# R7FA6T2BD register map
Vendor: Renesas Electronics Corporation; Series: RA6; File version: 1.40.00
CPU: CM33 r0p4, little endian, MPU, FPU, VTOR, 4 interrupt priority bits, 96 interrupts
Registers are 32-bit, read-write, reset 0x0 unless marked. A register's access mark holds for its fields unless they carry their own. Offsets are from the block's base; [hi:lo] are bit positions; lines under a group give offsets from that group; {n}, {i} and the like mark numbered series; 'fields as' and 'values as' point back to an identical list.

## ADC_B — 12-bit A/D Converter
Base 0x40170000
0x00 ADCLKENR — A/D Conversion Clock Enable Register
  [0] CLKEN — ADCLK Operating Enable
    0=Stop ADCLK; 1=Supply ADCLK
0x04 ADCLKSR ro — A/D Conversion Clock Status Register
  [0] CLKSR — ADCLK status
    0=ADCLK is stopped; 1=ADCLK is in supply
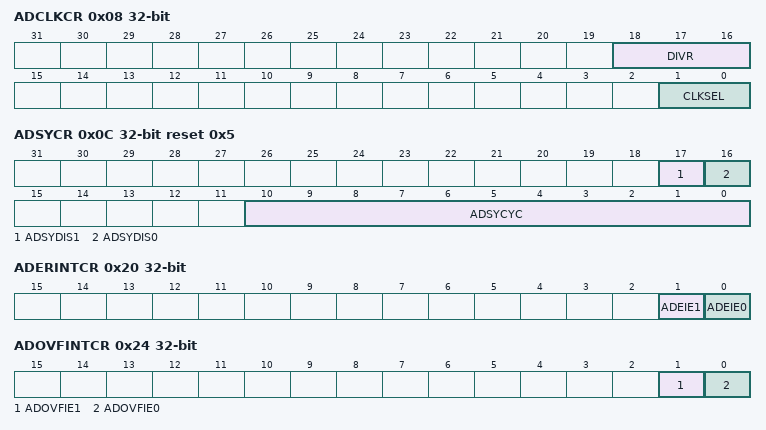
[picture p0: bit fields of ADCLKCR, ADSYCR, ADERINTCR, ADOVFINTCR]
0x08 ADCLKCR — A/D Conversion Clock Control Register
  [18:16] DIVR — Clock Division Ratio Select
    {v}=1/{v+1} (v=0..7)
  [1:0] CLKSEL — ADCLK Clock Source Select
    0=Peripheral Module Clock C (PCLKC); 1=GPT clock (GPTCLK); 2=Peripheral Module Clock A (PCLKA); 3=Setting prohibited
0x0C ADSYCR reset 0x5 — A/D Converter Synchronous Operation Control Register
  [17] ADSYDIS1 — ADC1 Synchronous Operation Select
    0=Enable ADC1 synchronous operation; 1=Disable ADC1 synchronous operation
  [16] ADSYDIS0 — ADC0 Synchronous Operation Select
    0=Enable ADC0 synchronous operation; 1=Disable ADC0 synchronous operation
  [10:0] ADSYCYC — Synchronous Operation Period Cycle
0x20 ADERINTCR — A/D Conversion Error Interrupt Enable Register
  [1] ADEIE1 — ADC1 A/D Conversion Error Interrupt Enable
    0=Disable A/D conversion error interrupt for ADC1; 1=Enable A/D conversion error interrupt for ADC1
  [0] ADEIE0 — ADC0 A/D Conversion Error Interrupt Enable
    0=Disable A/D conversion error interrupt for ADC0; 1=Enable A/D conversion error interrupt for ADC0
0x24 ADOVFINTCR — A/D Conversion Overflow Interrupt Enable Register
  [1] ADOVFIE1 — ADC1 A/D Conversion Overflow Interrupt Enable
    0=Disable A/D conversion overflow interrupt for ADC1; 1=Enable A/D conversion overflow interrupt for ADC1
  [0] ADOVFIE0 — ADC0 A/D Conversion Overflow Interrupt Enable
    0=Disable A/D conversion overflow interrupt for ADC0; 1=Enable A/D conversion overflow interrupt for ADC0
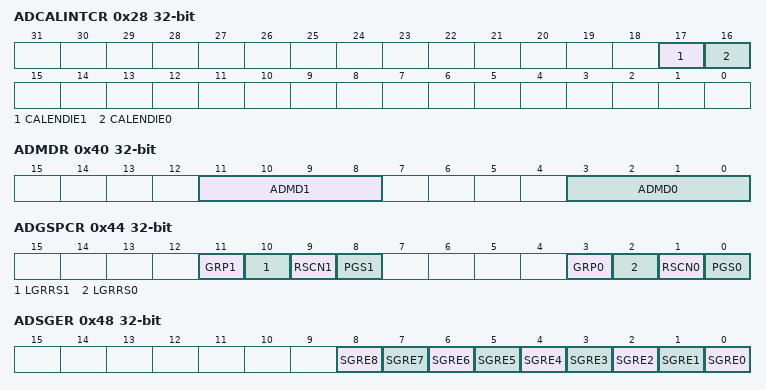
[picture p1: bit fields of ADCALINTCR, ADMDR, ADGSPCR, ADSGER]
0x28 ADCALINTCR — Calibration interrupt Enable Register
  [17] CALENDIE1 — ADC1 Calibration End Interrupt Enable
    0=Disable Calibration End Interrupt for ADC1; 1=Enable Calibration End Interrupt for ADC1
  [16] CALENDIE0 — ADC0 Calibration End Interrupt Enable
    0=Disable Calibration End Interrupt for ADC0; 1=Enable Calibration End Interrupt for ADC0
0x40 ADMDR — A/D Converter Mode Selection Register
  [11:8] ADMD1 — ADC1 Mode Selection
    0=SAR mode – Single scan mode; 1=SAR mode – Continuous scan mode; 4=Oversampling mode – Single scan mode; 5=Oversampling mode – Continuous scan mode; 8=Hybrid mode – Single scan mode; 9=Hybrid mode – Continuous scan mode; 10=Hybrid mode – Background continuous scan mode; other=Others (Setting prohibited)
  [3:0] ADMD0 — ADC0 Mode Selection
    values as ADMD1
0x44 ADGSPCR — A/D Group scan Priority Control Register
  [11] GRP1 — ADC1 Group Priority Control Setting 4
    0=Set the following case: When PGS1 is set to 0When PGS1 is set to 1 and ADC1 is SAR mode – Single scan mode; 1=Set when PGS1 is set to 1 and ADC1 is SAR mode – Continuous scan mode
  [10] LGRRS1 — ADC1 Group Priority Control Setting 3
    0=Set when PGS1 is set to 0; 1=Set when PGS1 is set to 1
  [9] RSCN1 — ADC1 Group Priority Control Setting 2
    0=Set when PGS1 is set to 0; 1=Set when PGS1 is set to 1
  [8] PGS1 — ADC1 Group Priority Control Setting
    0=ADC1 operation is without group priority control; 1=ADC1 operation is with group priority control in SAR mode. Setting prohibited when other than SAR mode.
  [3] GRP0 — ADC0 Group Priority Control Setting 4
    0=Set the following case: When PGS0 is set to 0When PGS0 is set to 1 and ADC0 is SAR mode – Single scan mode; 1=Set when PGS0 is set to 1 and ADC0 is SAR mode – Continuous scan mode
  [2] LGRRS0 — ADC0 Group Priority Control Setting 3
    0=Set when PGS0 is set to 0; 1=Set when PGS0 is set to 1
  [1] RSCN0 — ADC0 Group Priority Control Setting 2
    0=Set when PGS0 is set to 0; 1=Set when PGS0 is set to 1
  [0] PGS0 — ADC0 Group Priority Control Setting
    0=ADC0 operation is without group priority control; 1=ADC0 operation is with group priority control in SAR mode. Setting prohibited when other than SAR mode.
0x48 ADSGER — Scan Group Enable Register
  [all] fields
    0=Disable the scan group n; 1=Enable the scan group n
  [n] SGRE{n} (n=0..8) — Scan Group n Enable
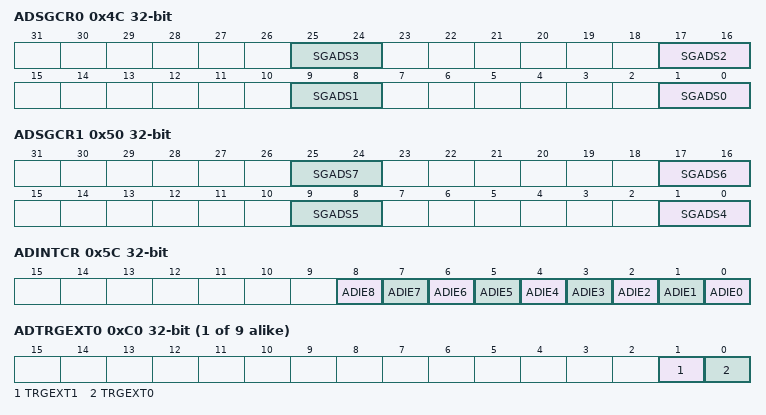
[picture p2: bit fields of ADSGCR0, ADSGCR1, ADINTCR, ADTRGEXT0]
0x4C ADSGCR0 — Scan Group Control Register 0
  [all] fields
    0=Select ADC0; 1=Select ADC1; other=Others (Setting prohibited)
  [8n+1:8n] SGADS{n} (n=0..3) — Scan Group {n} A/D Converter Selection
0x50 ADSGCR1 — Scan Group Control Register 1
  [all] fields
    values as the fields of ADSGCR0
  [8n-31:8n-32] SGADS{n} (n=4..7) — Scan Group {n} A/D Converter Selection
0x54 ADSGCR2 — Scan Group Control Register 2
  [1:0] SGADS8 — Scan Group 8 A/D Converter Selection
    values as the fields of ADSGCR0
0x5C ADINTCR — Scan End Interrupt Enable Register
  [all] fields
    0=Disable scan end interrupt; 1=Enable scan end interrupt
  [n] ADIE{n} (n=0..8) — Scan Group n Scan End Interrupt Enable
{0xC0+0x10*i} ADTRGEXT{i} (i=0..8) — External Trigger Enable Register {i}
  [1] TRGEXT1 — External Trigger Input 1 (ADTRG1) Enable
    0=Disable ADTRG1; 1=Enable ADTRG1
  [0] TRGEXT0 — External Trigger Input 0 (ADTRG0) Enable
    0=Disable ADTRG0; 1=Enable ADTRG0
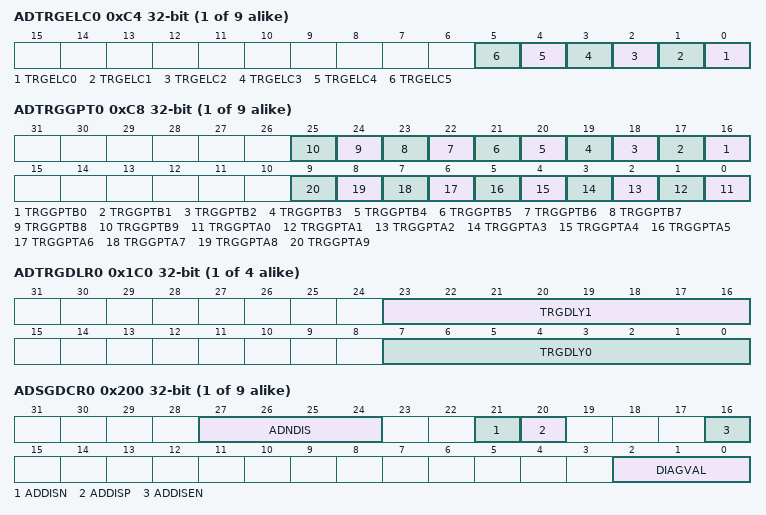
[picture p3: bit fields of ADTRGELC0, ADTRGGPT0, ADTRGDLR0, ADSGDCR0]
{0xC4+0x10*i} ADTRGELC{i} (i=0..8) — ELC Trigger Enable Register {i}
  [all] fields
    0=Disable ELC Trigger m; 1=Enable ELC Trigger m
  [n] TRGELC{n} (n=0..5) — ELC Trigger m Enable
{0xC8+0x10*i} ADTRGGPT{i} (i=0..8) — GPT Trigger Enable Register {i}
  [n+16] TRGGPTB{n} (n=0..9) — GPT channel m A/D Conversion Starting Request B Enable
    0=Disable the A/D conversion stating request B from GPT channel m; 1=Enable the A/D conversion stating request B from GPT channel m
  [n] TRGGPTA{n} (n=0..9) — GPT channel m A/D Conversion Starting Request A Enable
    0=Disable the A/D conversion stating request A from GPT channel m; 1=Enable the A/D conversion stating request A from GPT channel m
{0x1C0+4i} ADTRGDLR{i} (i=0..3) — A/D Conversion Start Trigger Delay Register {i}
  [23:16] TRGDLY{2i+1} — Scan Group {2i+1} Trigger Input Delay Configuration
  [7:0] TRGDLY{2i} — Scan Group {2i} Trigger Input Delay Configuration
0x1D0 ADTRGDLR4 — A/D Conversion Start Trigger Delay Register 4
  [7:0] TRGDLY8 — Scan Group 8 Trigger Input Delay Configuration
{0x200+4i} ADSGDCR{i} (i=0..8) — Scan Group Diagnosis Function Control Register {i}
  [27:24] ADNDIS — Disconnection Detection Assist Period
    0=Setting prohibited when the disconnection detection assist function is enabled; 1=Setting prohibited; 2=Setting prohibited; other=Others (The number of states for the discharge or precharge period)
  [21] ADDISN — Disconnection Detection Assist Mode Selection
    0=Discharge; 1=Precharge
  [20] ADDISP — Disconnection Detection Assist Mode Selection
    0=Discharge; 1=Precharge
  [16] ADDISEN — Disconnection Detection Assist Enable
    0=Disable the disconnection detection assist function; 1=Enable the disconnection detection assist function
  [2:0] DIAGVAL — Self-diagnosis Mode Selection
    0=Set when any self-diagnosis channel are not included. Setting prohibited when any self-diagnosis channels are included.; 4=Self-diagnosis mode 1; 5=Self-diagnosis mode 2; 6=Self-diagnosis mode 3; other=Others (Setting prohibited)
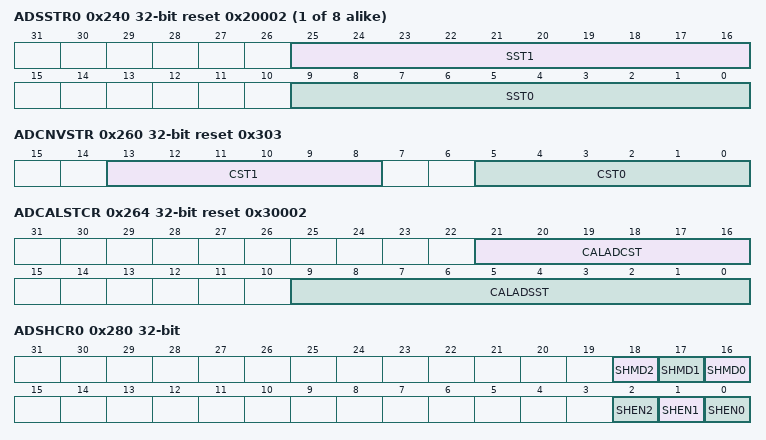
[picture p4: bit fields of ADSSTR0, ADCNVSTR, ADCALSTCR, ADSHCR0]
{0x240+4i} ADSSTR{i} reset 0x20002 (i=0..7) — Sampling State Table Register {i}
  [25:16] SST{2i+1} — Sampling State Table {2i+1}
  [9:0] SST{2i} — Sampling State Table {2i}
0x260 ADCNVSTR reset 0x303 — A/D Conversion State Register
  [13:8] CST1 — A/D Converter Unit 1 (ADC1)
  [5:0] CST0 — A/D Converter Unit 0 (ADC0)
0x264 ADCALSTCR reset 0x30002 — A/D Converter Self-calibration State Register
  [21:16] CALADCST — A/D Converter Self-calibration Successive Approximation Time Configuration.
  [9:0] CALADSST — A/D Converter Self-calibration Sampling Time Configuration
0x280 ADSHCR0 — Channel-dedicated Sample-and-hold Circuit Control Register 0
  [18] SHMD2 — Channel-dedicated Sample-and-hold Circuit Unit 2 Input Mode Select
    0=Single-ended Input mode; 1=Differential Input mode
  [17] SHMD1 — Channel-dedicated Sample-and-hold Circuit Unit 1 Input Mode Select
    0=Single-ended Input mode; 1=Differential Input mode
  [16] SHMD0 — Channel-dedicated Sample-and-hold Circuit Unit 0 Input Mode Select
    0=Single-ended Input mode; 1=Differential Input mode
  [2] SHEN2 — Channel-dedicated Sample-and-hold Circuit Unit 2 Select
    0=Bypass the circuit unit 2; 1=Use the circuit unit 2
  [1] SHEN1 — Channel-dedicated Sample-and-hold Circuit Unit 1 Select
    0=Bypass the circuit unit 1; 1=Use the circuit unit 1
  [0] SHEN0 — Channel-dedicated Sample-and-hold Circuit Unit 0 Select
    0=Bypass the circuit unit 0; 1=Use the circuit unit 0
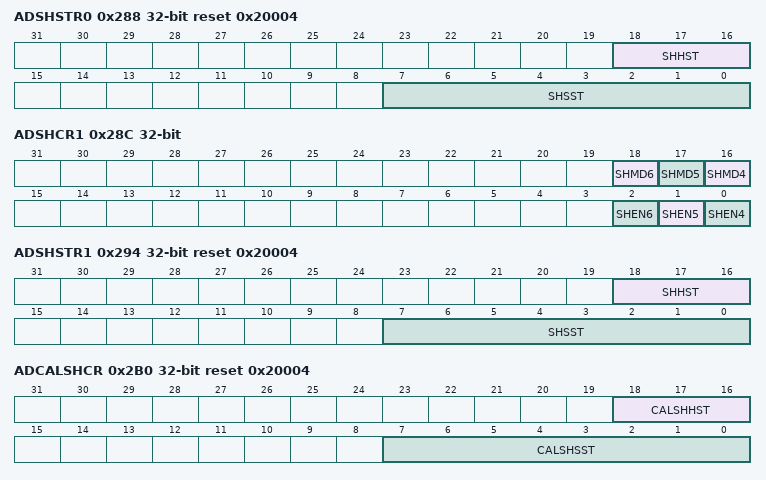
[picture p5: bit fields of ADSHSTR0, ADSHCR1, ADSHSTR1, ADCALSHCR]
0x288 ADSHSTR0 reset 0x20004 — Channel-dedicated Sample-and-hold Circuit State Register 0
  [18:16] SHHST — Channel-dedicated Sample-and-hold Circuit Unit 0 to 2
  [7:0] SHSST — Channel-dedicated Sample-and-hold Circuit Unit 0 to 2
0x28C ADSHCR1 — Channel-dedicated Sample-and-hold Circuit Control Register 1
  [18] SHMD6 — Channel-dedicated Sample-and-hold Circuit Unit 6 Input Mode Select
    0=Single-ended Input mode; 1=Differential Input mode
  [17] SHMD5 — Channel-dedicated Sample-and-hold Circuit Unit 5 Input Mode Select
    0=Single-ended Input mode; 1=Differential Input mode
  [16] SHMD4 — Channel-dedicated Sample-and-hold Circuit Unit 4 Input Mode Select
    0=Single-ended Input mode; 1=Differential Input mode
  [2] SHEN6 — Channel-dedicated Sample-and-hold Circuit Unit 6 Select
    0=Bypass the circuit unit 6; 1=Use the circuit unit 6
  [1] SHEN5 — Channel-dedicated Sample-and-hold Circuit Unit 5 Select
    0=Bypass the circuit unit 5; 1=Use the circuit unit 5
  [0] SHEN4 — Channel-dedicated Sample-and-hold Circuit Unit 4 Select
    0=Bypass the circuit unit 4; 1=Use the circuit unit 4
0x294 ADSHSTR1 reset 0x20004 — Channel-dedicated Sample-and-hold Circuit State Register 1
  [18:16] SHHST — Channel-dedicated Sample-and-hold Circuit Unit 4 to 6
  [7:0] SHSST — Channel-dedicated Sample-and-hold Circuit Unit 4 to 6
0x2B0 ADCALSHCR reset 0x20004 — Channel-dedicated Sample-and-hold Circuit Self-calibration State Register
  [18:16] CALSHHST — Channel-dedicated Sample-and-hold Circuit Self-calibration Hold Mode Switching Time Configuration
  [7:0] CALSHSST — Channel-dedicated Sample-and-hold Circuit Self-calibration Sampling Time Configuration
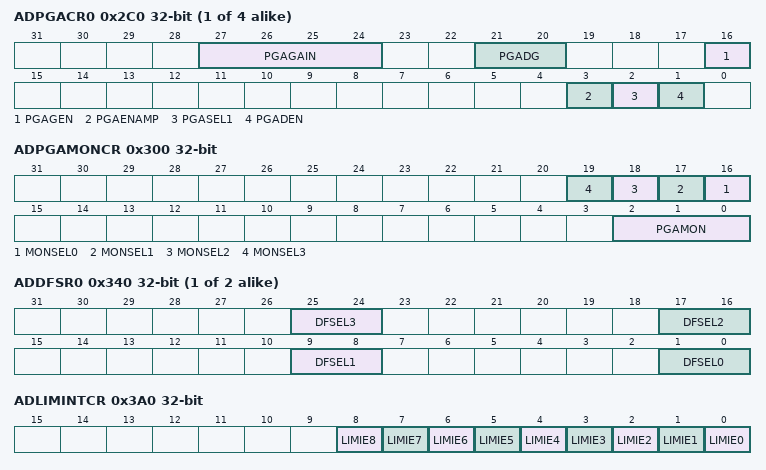
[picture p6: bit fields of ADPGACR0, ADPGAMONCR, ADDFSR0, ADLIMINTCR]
{0x2C0+4i} ADPGACR{i} (i=0..3) (reset mask 0xFFFFFFFD) — Programmable Gain Amplifier Control Register {i}
  [27:24] PGAGAIN — PGA Unit n Gain Setting
    0=× 2.000 (PGA is Single-ended Input mode) Setting prohibited (PGA is Pseudo-differential Input mode); 1=× 2.500 (PGA is Single-ended Input mode) × 1.500 (PGA is Pseudo-differential Input mode); 2=× 2.667 (PGA is Single-ended Input mode) Setting prohibited (PGA is Pseudo-differential Input mode); 3=× 2.857 (PGA is Single-ended Input mode) Setting prohibited (PGA is Pseudo-differential Input mode); 4=× 3.077 (PGA is Single-ended Input mode) Setting prohibited (PGA is Pseudo-differential Input mode); 5=× 3.333 (PGA is Single-ended Input mode) × 2.333 (PGA is Pseudo-differential Input mode); 6=× 3.636 (PGA is Single-ended Input mode) Setting prohibited (PGA is Pseudo-differential Input mode); 7=× 4.000 (PGA is Single-ended Input mode) Setting prohibited (PGA is Pseudo-differential Input mode); 8=× 4.444 (PGA is Single-ended Input mode) Setting prohibited (PGA is Pseudo-differential Input mode); 9=× 5.000 (PGA is Single-ended Input mode) × 4.000 (PGA is Pseudo-differential Input mode); 10=× 5.714 (PGA is Single-ended Input mode) Setting prohibited (PGA is Pseudo-differential Input mode); 11=× 6.667 (PGA is Single-ended Input mode) × 5.667 (PGA is Pseudo-differential Input mode); 12=× 8.000 (PGA is Single-ended Input mode) Setting prohibited (PGA is Pseudo-differential Input mode); 13=× 10.000 (PGA is Single-ended Input mode) Setting prohibited (PGA is Pseudo-differential Input mode); 14=× 13.333 (PGA is Single-ended Input mode) Setting prohibited (PGA is Pseudo-differential Input mode); 15=Setting prohibited
  [21:20] PGADG — PGA Unit n Differential Input Gain Setting
    0=× 1.500; 1=× 2.333; 2=× 4.000; 3=× 5.667
  [16] PGAGEN — PGA Unit n Gain Setting Enable
    0=Disable gain setting; 1=Enable gain setting
  [3] PGAENAMP — PGA Unit n Enable
    0=Disable the PGA; 1=Enable the PGA
  [2] PGASEL1 — PGA Unit n Amplifier Output Enable
    0=Not output the signal in a path through the PGA; 1=Output the signal in a path through the PGA
  [1] PGADEN — PGA Unit n Input Mode Select
    0=Single-ended Input mode; 1=Pseudo-differential Input mode
0x300 ADPGAMONCR — Programable Gain Amp Monitor Output Control Register
  [n+16] MONSEL{n} (n=0..3) — PGA Unit {n} Monitor Output Enable
    0=Disable monitor output; 1=Enable monitor output
  [2:0] PGAMON — PGA Monitor Signal Selection
    0=Not select monitor signal (Hi-Z); 1=PGA output; other=Others (Setting prohibited)
0x320 ADREFCR — Internal Reference Voltage Monitor Enable Register
  [0] VDE — Internal Reference Voltage A/D Conversion Select
    0=Disable A/D conversion of internal reference voltage; 1=Enable A/D conversion of internal reference voltage
{0x340+4i} ADDFSR{i} (i=0..1) — A/D Converter Digital Filter Selection Register {i}
  [all] fields
    1=Sinc filter; 2=Minimum phase filter; other=Others (Setting prohibited)
  [25:24] DFSEL3 — A/D Converter Unit n the 4th Digital Filter Characteristic Selection
  [17:16] DFSEL2 — A/D Converter Unit n the 3rd Digital Filter Characteristic Selection
  [9:8] DFSEL1 — A/D Converter Unit n the 2nd Digital Filter Characteristic Selection
  [1:0] DFSEL0 — A/D Converter Unit n the 1st Digital Filter Characteristic Selection
{0x360+4i} ADUOFTR{i} (i=0..7) — User Offset Table Register {i}
  [15:0] UOFSET — User Offset Table n
{0x380+4i} ADUGTR{i} (i=0..7) reset 0x400000 — User Gain Table Register {i}
  [23:0] UGAIN — User Gain Table n
0x3A0 ADLIMINTCR — Limiter Clip Interrupt Enable Register
  [all] fields
    0=Disable the limiter clip interrupt n; 1=Enable the limiter clip interrupt n
  [n] LIMIE{n} (n=0..8) — Limiter Clip Interrupt n Enable bit
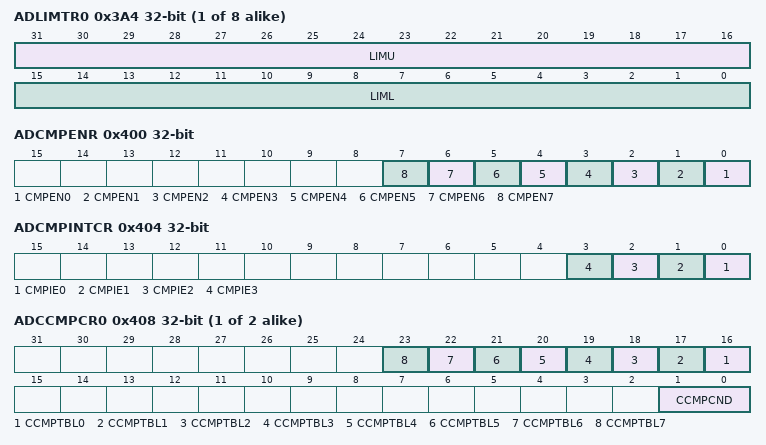
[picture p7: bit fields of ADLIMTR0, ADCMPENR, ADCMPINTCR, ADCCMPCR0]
{0x3A4+4i} ADLIMTR{i} (i=0..7) — Limiter Clip Table Register {i}
  [31:16] LIMU — Limiter clip table n : Upper-side limit value
  [15:0] LIML — Limiter clip table n : Lower-side limit value
0x400 ADCMPENR — Compare Match Enable Register
  [all] fields
    0=Disable the compare match n; 1=Enable the compare match n
  [n] CMPEN{n} (n=0..7) — Compare Match n Enable
0x404 ADCMPINTCR — Compare Match Interrupt Enable Register
  [all] fields
    0=Disable the compare match interrupt n; 1=Enable the compare match interrupt n
  [n] CMPIE{n} (n=0..3) — Compare Match Interrupt n Enable
{0x408+4i} ADCCMPCR{i} (i=0..1) — Composite Compare Match Configuration Register {i}
  [n+16] CCMPTBL{n} (n=0..7) — Composite Compare Match Condition Table Selection
    0=Not use the compare match table m; 1=Use the compare match table m
  [1:0] CCMPCND — Composite Compare Match Condition Selection
    0=Logical disjunction (OR) conditions; 1=Logical conjunction (AND) conditions; 2=Logical exclusive disjunction (EXOR) conditions; 3=Setting prohibited
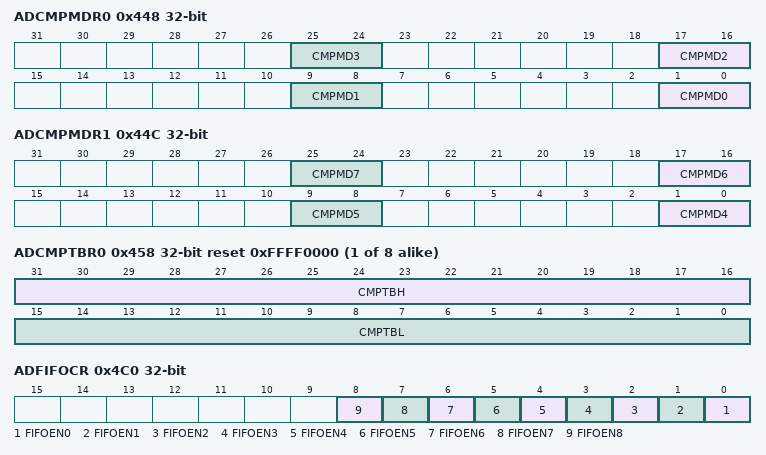
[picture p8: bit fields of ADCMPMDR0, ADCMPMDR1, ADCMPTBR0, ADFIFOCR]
0x448 ADCMPMDR0 — Compare Match Mode Selection Register 0
  [all] fields
    0=Generate the match event when high-side level or more; 1=Generate the match event when low-side level or less; 2=Generate the match event when high-side level or more, or low-side level or less; 3=Generate the match event when low-side level or more and high-side level or less
  [8n+1:8n] CMPMD{n} (n=0..3) — Compare Match {n} : Match Mode Selection
0x44C ADCMPMDR1 — Compare Match Mode Selection Register 1
  [all] fields
    values as the fields of ADCMPMDR0
  [8n-31:8n-32] CMPMD{n} (n=4..7) — Compare Match {n} : Match Mode Selection
{0x458+4i} ADCMPTBR{i} (i=0..7) reset 0xFFFF0000 — Compare Match Table Register {i}
  [31:16] CMPTBH — Compare Match Table n : High-side level
  [15:0] CMPTBL — Compare Match Table n : Low-side level
0x4C0 ADFIFOCR — FIFO Control Register
  [all] fields
    0=Disable scan group n FIFO function; 1=Enable scan group n FIFO function
  [n] FIFOEN{n} (n=0..8) — Scan Group n FIFO Enable
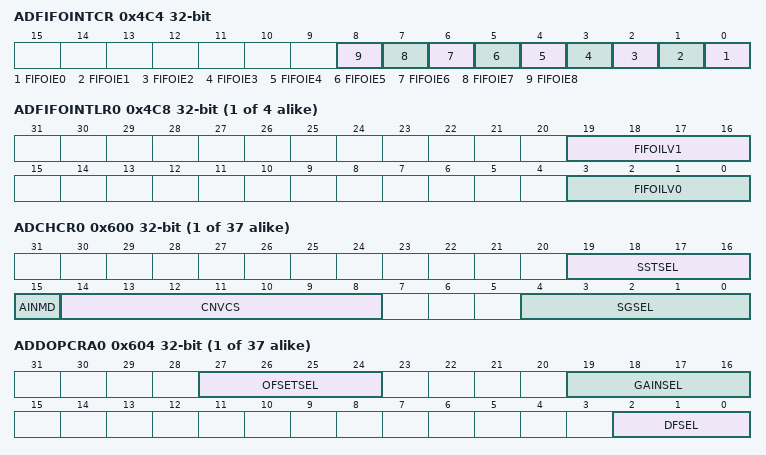
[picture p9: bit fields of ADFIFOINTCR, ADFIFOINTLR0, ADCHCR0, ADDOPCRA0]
0x4C4 ADFIFOINTCR — FIFO Interrupt Control Register
  [all] fields
    0=Disable scan group n FIFO interrupt; 1=Enable scan group n FIFO interrupt
  [n] FIFOIE{n} (n=0..8) — Scan Group n FIFO Interrupt Enable
{0x4C8+4i} ADFIFOINTLR{i} (i=0..3) — FIFO Interrupt Generation Level Register {i}
  [19:16] FIFOILV{2i+1} — Scan Group {2i+1} FIFO Interrupt Output Timing Setting
  [3:0] FIFOILV{2i} — Scan Group {2i} FIFO Interrupt Output Timing Setting
0x4D8 ADFIFOINTLR4 — FIFO Interrupt Generation Level Register 4
  [3:0] FIFOILV8 — Scan Group 8 FIFO Interrupt Output Timing Setting
{0x600+0x10*i} ADCHCR{i} (i=0..36) — A/D Conversion Channel Configuration Register {i}
  [19:16] SSTSEL — Sampling State Table Selection
  [15] AINMD — Analog Input mode selection
    0=Single-ended input; 1=Differential input
  [14:8] CNVCS — A/D Conversion Channel Selection
  [4:0] SGSEL — Scan Group Selection
{0x604+0x10*i} ADDOPCRA{i} (i=0..36) — A/D Conversion Data Operation Control A Register {i}
  [27:24] OFSETSEL — User Offset Table Selection
  [19:16] GAINSEL — User Gain Table Selection
  [2:0] DFSEL — Digital Filter Selection
    0=Not use the digital filter; 1=Use the 1st digital filter; 2=Use the 2nd digital filter; 3=Use the 3rd digital filter; 4=Use the 4th digital filter; other=Others (Setting prohibited)
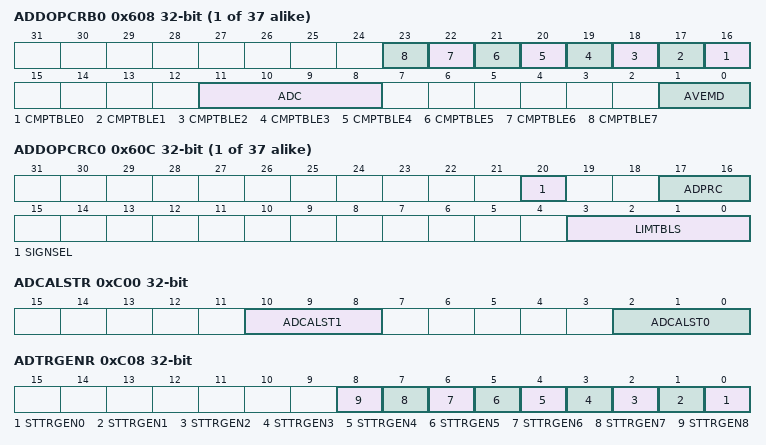
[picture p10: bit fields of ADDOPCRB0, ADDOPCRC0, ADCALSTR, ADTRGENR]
{0x608+0x10*i} ADDOPCRB{i} (i=0..36) — A/D Conversion Data Operation Control B Register {i}
  [n+16] CMPTBLE{n} (n=0..7) — Compare Match Enable
    0=Disable the compare match with the compare match table m; 1=Enable the compare match with the compare match table m
  [11:8] ADC — Addition/Averaging Times Selection
    0=1-time conversion (no addition, same as normal conversion); 1=2-time conversion (1 addition); 3=4-time conversion (3 additions); 4=8-time conversion (7 additions); 5=16-time conversion (15 additions); 6=32-time conversion (31 additions); 7=64-time conversion (63 additions); 8=128-time conversion (127 additions); 9=256-time conversion (255 additions); 10=512-time conversion (511 additions); 11=1024-time conversion (1023 additions); other=Others (Setting prohibited)
  [1:0] AVEMD — Addition/Averaging Mode Selection
    0=Not use Addition/Averaging mode; 1=Addition mode; 2=Averaging mode; 3=Setting prohibited
{0x60C+0x10*i} ADDOPCRC{i} (i=0..36) — A/D Conversion Data Operation Control C Register {i}
  [20] SIGNSEL — A/D Conversion Data Signed/Un-signed Selection
    0=Signed data format; 1=Un-signed data format
  [17:16] ADPRC — A/D Conversion Data Format Selection
    0=Store the A/D conversion result as 16-bit data format; 1=Store the A/D conversion result as 14-bit data format; 2=Store the A/D conversion result as 12-bit data format; 3=Store the A/D conversion result as 10-bit data format
  [3:0] LIMTBLS — Limiter Clip Table Selection
0xC00 ADCALSTR wo — A/D Converter Self-calibration Start Register
  [10:8] ADCALST1 — A/D Converter Unit 1 (ADC1) Self-calibration Start Control
  [2:0] ADCALST0 — A/D Converter Unit 0 (ADC0) Self-calibration Start Control
0xC08 ADTRGENR — A/D Conversion Start Trigger Enable Register
  [all] fields
    0=Disable the A/D conversion start trigger; 1=Enable the A/D conversion start trigger
  [n] STTRGEN{n} (n=0..8) — Scan Group n A/D Conversion Start Trigger Enable
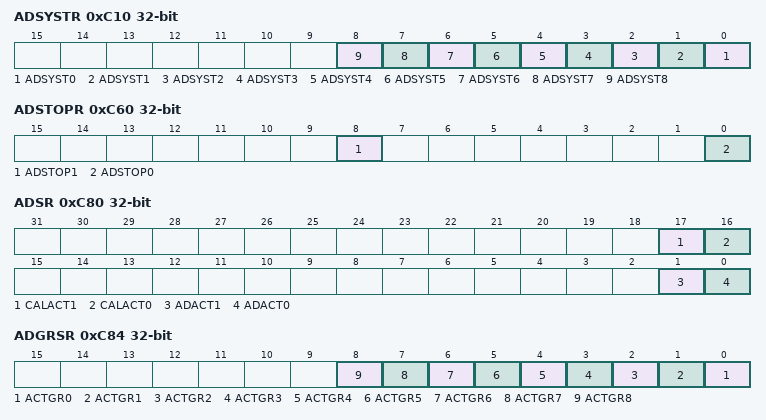
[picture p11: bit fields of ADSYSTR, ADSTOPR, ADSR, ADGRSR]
0xC10 ADSYSTR wo — A/D Conversion Synchronous Software Start Register
  [all] fields
    0=No effect; 1=Start the A/D conversion of scan group n
  [n] ADSYST{n} (n=0..8) — Scan Group n: A/D Conversion start
{0xC20+4i} ADSTR{i} (i=0..8) wo — A/D Conversion Software Start Register {i}
  [0] ADST — Scan Group n A/D Conversion Start
    0=No effect; 1=Start the A/D conversion of scan group n
0xC60 ADSTOPR wo — A/D Conversion Stop Register
  [8] ADSTOP1 — A/D Converter Unit 1 Force Stop
    0=No effect; 1=Force stop the operation of A/D converter unit 1
  [0] ADSTOP0 — A/D Converter Unit 0 Force Stop
    0=No effect; 1=Force stop the operation of A/D converter unit 0
0xC80 ADSR ro — A/D Conversion Status Register
  [17] CALACT1 — A/D Converter Unit 1 (ADC1) : Calibration Status
    0=ADC1 is not in the calibration operation; 1=ADC1 is in the calibration operation
  [16] CALACT0 — A/D Converter Unit 0 (ADC0) : Calibration Status
    0=ADC0 is not in the calibration operation; 1=ADC0 is in the calibration operation
  [1] ADACT1 — A/D Converter Unit 1 (ADC1) A/D Conversion Status
    0=ADC1 is not in A/D conversion; 1=ADC1 is in A/D conversion
  [0] ADACT0 — A/D Converter Unit 0 (ADC0) A/D Conversion Status
    0=ADC0 is not in A/D conversion; 1=ADC0 is in A/D conversion
0xC84 ADGRSR ro — Scan Group Status Register
  [all] fields
    0=Scan group n is idle; 1=Scan group n is in the scanning operation
  [n] ACTGR{n} (n=0..8) — Scan Group n Status
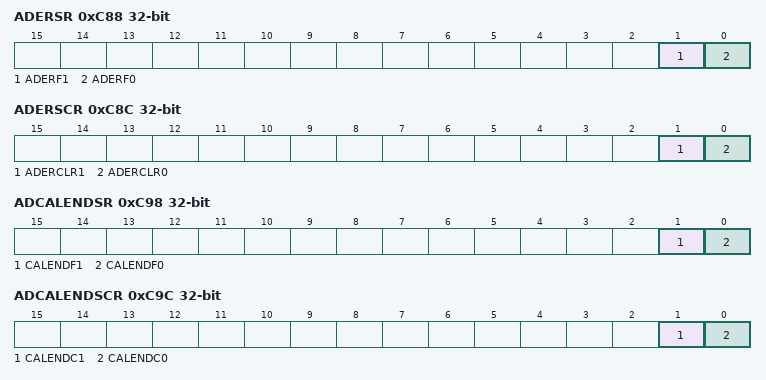
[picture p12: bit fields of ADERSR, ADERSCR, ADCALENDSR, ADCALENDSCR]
0xC88 ADERSR ro — A/D Conversion Error Status Register
  [1] ADERF1 — A/D Converter Unit 1 (ADC1) Error Flag
    0=Error is not detected; 1=Error is detected
  [0] ADERF0 — A/D Converter Unit 0 (ADC0) Error Flag
    0=Error is not detected; 1=Error is detected
0xC8C ADERSCR wo — A/D Conversion Error Status Clear Register
  [1] ADERCLR1 — A/D Converter Unit 1 Error Flag Clear
    0=No effect; 1=ADERSR.ADERF1 is cleared
  [0] ADERCLR0 — A/D Converter Unit 0 Error Flag Clear
    0=No effect; 1=ADERSR.ADERF0 is cleared
0xC98 ADCALENDSR ro — A/D Converter Calibration End Status Register
  [1] CALENDF1 — A/D Converter Unit 1 Calibration End flag
    0=End of the calibration is not detected; 1=End of the calibration is detected
  [0] CALENDF0 — A/D Converter Unit 0 Calibration End flag
    values as CALENDF1
0xC9C ADCALENDSCR wo — A/D Converter Calibration End Status Clear Register
  [1] CALENDC1 — A/D Converter Unit 1 Calibration End Flag Clear
    0=No effect; 1=ADCALENDSR.CALENDF1 is cleared
  [0] CALENDC0 — A/D Converter Unit 0 Calibration End Flag Clear
    0=No effect; 1=ADCALENDSR.CALENDF0 is cleared
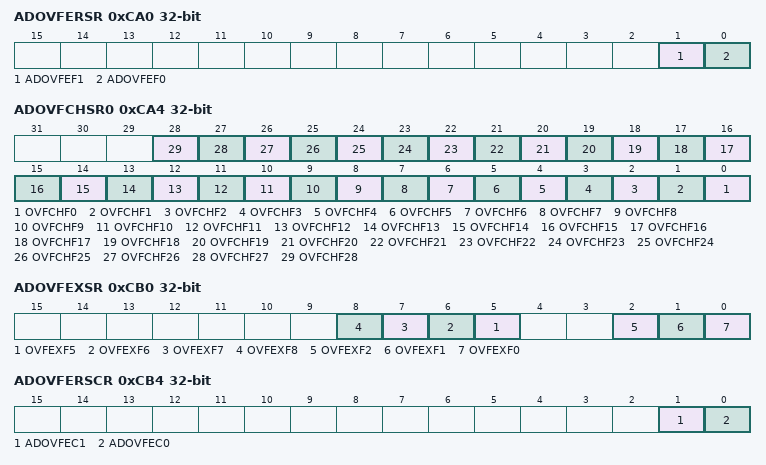
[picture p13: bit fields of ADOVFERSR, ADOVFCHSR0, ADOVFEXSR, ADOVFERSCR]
0xCA0 ADOVFERSR ro — A/D Conversion Overflow Error Status Register
  [1] ADOVFEF1 — A/D Converter Unit 1 (ADC1) Overflow Error Flag
    0=ADC1 overflow error is not detected; 1=ADC1 overflow error is detected
  [0] ADOVFEF0 — A/D Converter Unit 0 (ADC0) Overflow Error Flag
    0=ADC0 overflow error is not detected; 1=ADC0 overflow error is detected
0xCA4 ADOVFCHSR0 ro — A/D Conversion Overflow Channel Status Register 0
  [all] fields
    0=Overflow is not detected; 1=Overflow is detected
  [n] OVFCHF{n} (n=0..28) — Analog Channel n: Overflow Flag
0xCB0 ADOVFEXSR ro — Extended Analog A/D Conversion Overflow Status Register
  [all] fields
    0=Overflow is not detected; 1=Overflow is detected
  [n] OVFEXF{n} (n=5..8) — D/A Converter {n-5} Channel: Overflow Flag
  [2] OVFEXF2 — Internal Reference Voltage Channel: Overflow Flag
  [1] OVFEXF1 — Temperature Sensor Channel: Overflow Flag
  [0] OVFEXF0 — Self-diagnosis Channel: Overflow Flag
0xCB4 ADOVFERSCR wo — A/D Conversion Overflow Error Status Clear Register
  [1] ADOVFEC1 — A/D Converter Unit 1 (ADC1) Overflow Error Flag Clear
    0=No effect; 1=ADOVFERSR.ADOVFEF1 is cleared
  [0] ADOVFEC0 — A/D Converter Unit 0 (ADC0) Overflow Error Flag Clear
    0=No effect; 1=ADOVFERSR.ADOVFEF0 is cleared
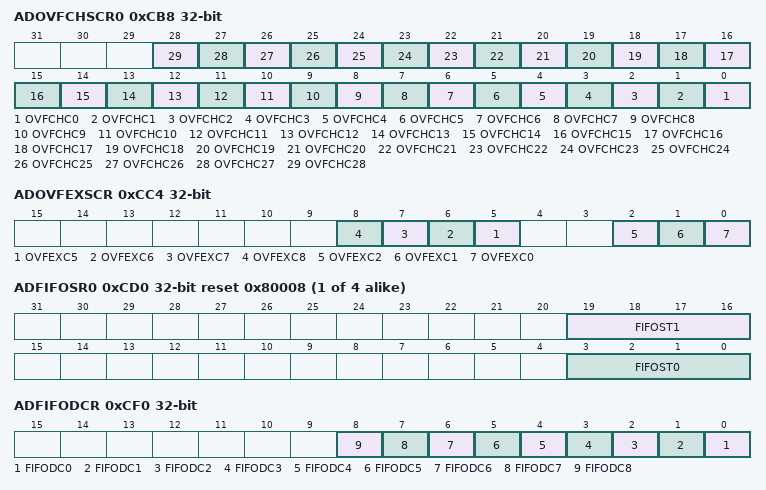
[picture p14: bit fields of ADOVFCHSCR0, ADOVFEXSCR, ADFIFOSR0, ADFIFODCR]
0xCB8 ADOVFCHSCR0 wo — A/D Conversion Overflow Channel Status Clear Register 0
  [all] fields
    0=No effect; 1=ADOVFCHSR0.OVFCHFn is cleared
  [n] OVFCHC{n} (n=0..28) — Analog Channel n: Overflow Flag Clear
0xCC4 ADOVFEXSCR wo — Extended Analog A/D Conversion Overflow Status Clear Register
  [n] OVFEXC{n} (n=5..8) — D/A Converter {n-5} Channel: Overflow Flag Clear
    0=No effect; 1=ADOVFEXSR.OVFEXF{n} is cleared
  [2] OVFEXC2 — Internal Reference Voltage Channel: Overflow Flag Clear
    0=No effect; 1=ADOVFEXSR.OVFEXF2 is cleared
  [1] OVFEXC1 — Temperature Sensor Channel: Overflow Flag Clear
    0=No effect; 1=ADOVFEXSR.OVFEXF1 is cleared
  [0] OVFEXC0 — Self-diagnosis Channel: Overflow Flag Clear
    0=No effect; 1=ADOVFEXSR.OVFEXF0 is cleared
{0xCD0+4i} ADFIFOSR{i} ro reset 0x80008 (i=0..3) — FIFO Status Register {i}
  [19:16] FIFOST{2i+1} — Number of vacant stages in FIFO for Scan Group {2i+1}
  [3:0] FIFOST{2i} — Number of vacant stages in FIFO for Scan Group {2i}
0xCE0 ADFIFOSR4 ro reset 0x8 — FIFO Status Register 4
  [3:0] FIFOST8 — Number of vacant stages in FIFO for Scan Group 8
0xCF0 ADFIFODCR wo — FIFO Data Clear Register
  [all] fields
    0=No effect; 1=Clear the data of scan group n FIFO
  [n] FIFODC{n} (n=0..8) — Scan Group n FIFO Data Clear
0xCF4 ADFIFOERSR ro — FIFO Error Status Register
  [n+16] FIFOFLF{n} (n=0..8) — Scan Group n FIFO Data Read Request Flag
    0=FIFO Data Read Request is not detected; 1=FIFO Data Read Request is detected
  [n] FIFOOVF{n} (n=0..8) — Scan Group n FIFO Overflow Flag
    0=No overflow; 1=FIFO overflow is detected
0xCF8 ADFIFOERSCR wo — FIFO Error Status Clear Register
  [n+16] FIFOFLC{n} (n=0..8) — Scan Group n FIFO Data Read Request Flag Clear
    0=No effect; 1=ADFIFOERSR.FIFOFLFn is cleared
  [n] FIFOOVFC{n} (n=0..8) — Scan Group n FIFO Overflow Flag Clear
    0=No effect; 1=ADFIFOERSR.FIFOOVFn is cleared
0xD00 ADCMPTBSR ro — Compare Match Table Status Register
  [all] fields
    0=Match event with compare match table n is not detected; 1=Match event with compare match table n is detected
  [n] CMPTBF{n} (n=0..7) — Compare Match Table n Match Flag
0xD04 ADCMPTBSCR wo — Compare Match Table Status Clear Register
  [all] fields
    0=No effect; 1=ADCMPTBSR.CMPTBFn is cleared
  [n] CMPTBC{n} (n=0..7) — Compare Match Table n: Match Flag Clear
0xD08 ADCMPCHSR0 ro — Compare Match Channel Status Register 0
  [all] fields
    0=Compare match is not detected; 1=Compare match is detected
  [n] CMPCHF{n} (n=0..28) — Analog Channel n: Compare Match Flag
0xD14 ADCMPEXSR ro — Extended Analog Compare Match Status Register
  [all] fields
    0=Compare match is not detected; 1=Compare match is detected
  [n] CMPEXF{n} (n=5..8) — D/A Converter {n-5} Channel: Compare Match Flag
  [2] CMPEXF2 — Internal Reference Voltage Channel: Compare Match Flag
  [1] CMPEXF1 — Temperature Sensor Channel: Compare Match Flag
  [0] CMPEXF0 — Self-diagnosis Channel: Compare Match Flag
0xD18 ADCMPCHSCR0 wo — Compare Match Channel Status Clear Register 0
  [all] fields
    0=No effect; 1=ADCMPCHSR0.CMPCHFn is cleared
  [n] CMPCHC{n} (n=0..28) — Analog Channel n: Compare Match Flag Clear bit
0xD24 ADCMPEXSCR wo — Extended Analog Compare Match Status Clear Register
  [n] CMPEXC{n} (n=5..8) — D/A Converter {n-5} Channel: Compare Match Flag Clear
    0=No effect; 1=ADCMPEXSR.CMPEXF{n} is cleared
  [2] CMPEXC2 — Internal Reference Voltage Channel: Compare Match Flag Clear
    0=No effect; 1=ADCMPEXSR.CMPEXF2 is cleared
  [1] CMPEXC1 — Temperature Sensor Channel: Compare Match Flag Clear
    0=No effect; 1=ADCMPEXSR.CMPEXF1 is cleared
  [0] CMPEXC0 — Self-diagnosis Channel: Compare Match Flag Clear
    0=No effect; 1=ADCMPEXSR.CMPEXF0 is cleared
0xD28 ADLIMGRSR ro — Limiter Clip Scan Group Status Register
  [all] fields
    0=Limiter clip for scan group n is not detected; 1=Limiter clip for scan group n is detected
  [n] LIMGRF{n} (n=0..8) — Scan Group n Limiter Clip Flag
0xD2C ADLIMCHSR0 ro — Limiter Clip Channel Status Register 0
  [all] fields
    0=Limiter clip is not detected; 1=Limiter clip is detected
  [n] LIMCHF{n} (n=0..28) — Analog Channel n: Limiter Clip Flag
0xD38 ADLIMEXSR ro — Extended Analog Limiter Clip Status Register
  [all] fields
    0=Limiter clip is not detected; 1=Limiter clip is detected
  [n] LIMEXF{n} (n=5..8) — D/A Converter {n-5} Channel: Limiter Clip Flag
  [2] LIMEXF2 — Internal Reference Voltage Channel: Limiter Clip Flag
  [1] LIMEXF1 — Temperature Sensor Channel: Limiter Clip Flag
  [0] LIMEXF0 — Self-diagnosis Channel: Limiter Clip Flag
0xD3C ADLIMGRSCR wo — Limiter Clip Scan Group Status Clear Register
  [all] fields
    0=No effect; 1=ADLIMGRSR.LIMGRFn is cleared
  [n] LIMGRC{n} (n=0..8) — Scan Group n Limiter Clip Flag Clear
0xD40 ADLIMCHSCR0 wo — Limiter Clip Channel Status Clear Register 0
  [all] fields
    0=No effect; 1=ADLIMCHSR0.LIMCHFn is cleared
  [n] LIMCHC{n} (n=0..28) — Analog Channel n Limiter Clip Flag Clear bit
0xD4C ADLIMEXSCR wo — Extended Analog Limiter Clip Status Clear Register
  [n] LIMEXF{n} (n=5..8) — D/A Converter {n-5} Channel: Limiter Clip Flag Clear
    0=No effect; 1=ADLIMEXSR.LIMEXF{n} is cleared
  [2] LIMEXF2 — Internal Reference Voltage Channel: Limiter Clip Flag Clear
    0=No effect; 1=ADLIMEXSR.LIMEXF2 is cleared
  [1] LIMEXF1 — Temperature Sensor Channel: Limiter Clip Flag Clear
    0=No effect; 1=ADLIMEXSR.LIMEXF1 is cleared
  [0] LIMEXF0 — Self-diagnosis Channel: Limiter Clip Flag Clear
    0=No effect; 1=ADLIMEXSR.LIMEXF0 is cleared
0xD50 ADSCANENDSR ro — Scan End Status Register
  [all] fields
    0=Scan group n has not been scanned; 1=End of scan for scan group n is detected
  [n] SCENDF{n} (n=0..8) — Scan Group n Scan End Flag
0xD54 ADSCANENDSCR wo — Scan End Status Clear Register
  [all] fields
    0=No effect; 1=ADSCANENDSR.SCENDFn is cleared
  [n] SCENDC{n} (n=0..8) — Scan Group n Scan End Flag Clear
{0x1000+4i} ADDR{i} (i=0..28) ro — A/D Data Register {i}
  [31] ERR — A/D conversion data error status
    0=No error (the A/D conversion data is valid); 1=Error is detected (the A/D conversion data is not guaranteed)
  [15:0] DATA — A/D conversion data
{0x1180+4i} ADEXDR{i} (i=0..2) ro — A/D Extended Analog Data Register {i}
  [31] ERR — A/D Conversion Error Status
    values as ADDR0.ERR
  [26:24] DIAGSR — Self-diagnosis Status
  [15:0] DATA — A/D conversion data
{0x1180+4i} ADEXDR{i} (i=5..8) ro — A/D Extended Analog Data Register {i}
  fields as ADEXDR0
{0x1200+4i} ADFIFODR{i} (i=0..8) ro — FIFO Data Register {i}
  [31] ERR — A/D Conversion Data Error Status
    values as ADDR0.ERR
  [30:24] CH — A/D Conversion Channel Number
  [15:0] DATA — A/D Conversion Data
